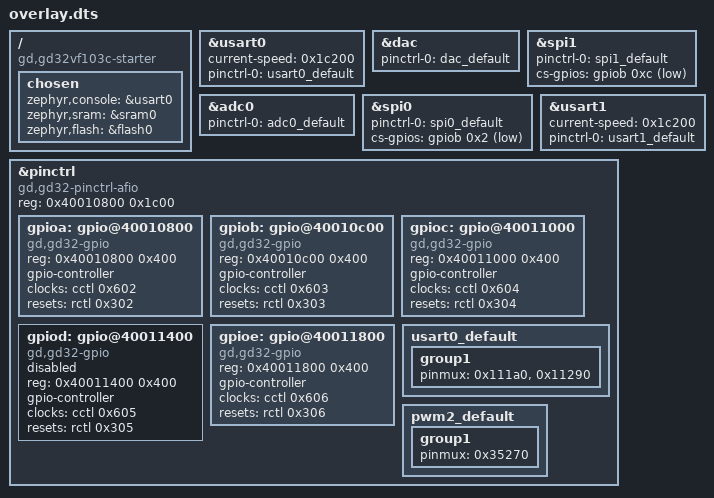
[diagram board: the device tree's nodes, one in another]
/ {
	compatible = "gd,gd32vf103c-starter";
	chosen {
		zephyr,console = &usart0;
		zephyr,sram = &sram0;
		zephyr,flash = &flash0;
	};
};
&gpiob{
	status = "okay";
};
&gpioe{
	status = "okay";
};
&usart0{
	status = "okay";
	current-speed = < 0x1c200 >;
	pinctrl-0 = < &usart0_default >;
	pinctrl-names = "default";
};
&gpioc{
	status = "okay";
};
&gpioa{
	status = "okay";
};
&dac{
	status = "okay";
	pinctrl-0 = < &dac_default >;
	pinctrl-names = "default";
};
&spi1{
	status = "okay";
	pinctrl-0 = < &spi1_default >;
	pinctrl-names = "default";
	cs-gpios = < &gpiob 0xc 0x1 >;
};
&adc0{
	status = "okay";
	pinctrl-0 = < &adc0_default >;
	pinctrl-names = "default";
};
&spi0{
	status = "okay";
	pinctrl-0 = < &spi0_default >;
	pinctrl-names = "default";
	cs-gpios = < &gpiob 0x2 0x1 >;
};
&usart1{
	status = "okay";
	current-speed = < 0x1c200 >;
	pinctrl-0 = < &usart1_default >;
	pinctrl-names = "default";
};
&pinctrl{
	compatible = "gd,gd32-pinctrl-afio";
	reg = < 0x40010800 0x1c00 >;
	#address-cells = < 0x1 >;
	#size-cells = < 0x1 >;
	status = "okay";
	gpioa: gpio@40010800 {
		compatible = "gd,gd32-gpio";
		reg = < 0x40010800 0x400 >;
		gpio-controller;
		#gpio-cells = < 0x2 >;
		clocks = < &cctl 0x602 >;
		resets = < &rctl 0x302 >;
		status = "okay";
	};
	gpiob: gpio@40010c00 {
		compatible = "gd,gd32-gpio";
		reg = < 0x40010c00 0x400 >;
		gpio-controller;
		#gpio-cells = < 0x2 >;
		clocks = < &cctl 0x603 >;
		resets = < &rctl 0x303 >;
		status = "okay";
	};
	gpioc: gpio@40011000 {
		compatible = "gd,gd32-gpio";
		reg = < 0x40011000 0x400 >;
		gpio-controller;
		#gpio-cells = < 0x2 >;
		clocks = < &cctl 0x604 >;
		resets = < &rctl 0x304 >;
		status = "okay";
	};
	gpiod: gpio@40011400 {
		compatible = "gd,gd32-gpio";
		reg = < 0x40011400 0x400 >;
		gpio-controller;
		#gpio-cells = < 0x2 >;
		clocks = < &cctl 0x605 >;
		resets = < &rctl 0x305 >;
		status = "disabled";
	};
	gpioe: gpio@40011800 {
		compatible = "gd,gd32-gpio";
		reg = < 0x40011800 0x400 >;
		gpio-controller;
		#gpio-cells = < 0x2 >;
		clocks = < &cctl 0x606 >;
		resets = < &rctl 0x306 >;
		status = "okay";
	};
	usart0_default: usart0_default {
		group1 {
			pinmux = < 0x111a0 >, < 0x11290 >;
		};
	};
	pwm2_default: pwm2_default {
		group1 {
			pinmux = < 0x35270 >;
		};
	};
};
